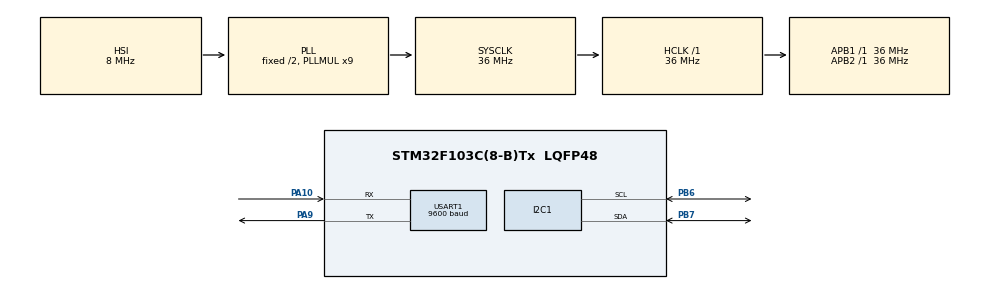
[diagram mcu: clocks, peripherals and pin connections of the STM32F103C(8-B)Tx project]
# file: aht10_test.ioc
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Mcu.Family=STM32F1
Mcu.Name=STM32F103C(8-B)Tx
Mcu.Package=LQFP48
NVIC.PriorityGroup=NVIC_PRIORITYGROUP_4
NVIC.TIM3_IRQn=true\:15\:0\:false\:false\:true\:false\:true\:true
NVIC.TimeBase=TIM3_IRQn
NVIC.TimeBaseIP=TIM3
PA10.Mode=Asynchronous
PA10.Signal=USART1_RX
PA13.Mode=Serial_Wire
PA13.Signal=SYS_JTMS-SWDIO
PA14.Mode=Serial_Wire
PA14.Signal=SYS_JTCK-SWCLK
PA9.Mode=Asynchronous
PA9.Signal=USART1_TX
PB6.Mode=I2C
PB6.Signal=I2C1_SCL
PB7.Mode=I2C
PB7.Signal=I2C1_SDA
ProjectManager.HeapSize=0x200
ProjectManager.StackSize=0x400
ProjectManager.TargetToolchain=STM32CubeIDE
RCC.AHBFreq_Value=36000000
RCC.APB1Freq_Value=36000000
RCC.APB1TimFreq_Value=36000000
RCC.APB2Freq_Value=36000000
RCC.APB2TimFreq_Value=36000000
RCC.HCLKFreq_Value=36000000
RCC.PLLMUL=RCC_PLL_MUL9
RCC.SYSCLKFreq_VALUE=36000000
RCC.SYSCLKSource=RCC_SYSCLKSOURCE_PLLCLK
RCC.USBFreq_Value=36000000
USART1.BaudRate=9600
USART1.VirtualMode=VM_ASYNC
VP_SYS_VS_tim3.Mode=TIM3
board=custom

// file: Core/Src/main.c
/* USER CODE BEGIN Header */
/**
  ******************************************************************************
  * @file           : main.c
  * @brief          : Main program body
  ******************************************************************************
  * @attention
  *
  * Copyright (c) 2022 STMicroelectronics.
  * All rights reserved.
  *
  * This software is licensed under terms that can be found in the LICENSE file
  * in the root directory of this software component.
  * If no LICENSE file comes with this software, it is provided AS-IS.
  *
  ******************************************************************************
  */
/* USER CODE END Header */
#include "main.h"
#include "i2c.h"
#include "usart.h"
#include "gpio.h"

/* USER CODE BEGIN Includes */
#include "stdio.h"
#include "aht10.h"
/* USER CODE END Includes */

void SystemClock_Config(void);

/* USER CODE BEGIN 0 */
#ifdef __GNUC__
  #define PUTCHAR_PROTOTYPE int __io_putchar(int ch)
#else
  #define PUTCHAR_PROTOTYPE int fputc(int ch, FILE *f)
#endif

PUTCHAR_PROTOTYPE
{
	huart1.Instance->DR = (uint8_t) ch;
//	HAL_UART_Transmit(&huart1,(uint8_t *)&ch,1,0xFFFF);
	while(__HAL_UART_GET_FLAG(&huart1, UART_FLAG_TC) == RESET){}
  return ch;
}
/* USER CODE END 0 */

int main(void)
{

  /* MCU Configuration--------------------------------------------------------*/

  /* Reset of all peripherals, Initializes the Flash interface and the Systick. */
  HAL_Init();

  /* Configure the system clock */
  SystemClock_Config();

  /* Initialize all configured peripherals */
  MX_GPIO_Init();
  MX_I2C1_Init();
  MX_USART1_UART_Init();
  /* USER CODE BEGIN 2 */
  aht10_init();
  /* USER CODE END 2 */

  /* Infinite loop */
  while (1)
  {
	  aht10_read_data();
	  HAL_Delay(2000);
  }
}

void SystemClock_Config(void)
{
  RCC_OscInitTypeDef RCC_OscInitStruct = {0};
  RCC_ClkInitTypeDef RCC_ClkInitStruct = {0};

  /** Initializes the RCC Oscillators according to the specified parameters
  * in the RCC_OscInitTypeDef structure.
  */
  RCC_OscInitStruct.OscillatorType = RCC_OSCILLATORTYPE_HSI;
  RCC_OscInitStruct.HSIState = RCC_HSI_ON;
  RCC_OscInitStruct.HSICalibrationValue = RCC_HSICALIBRATION_DEFAULT;
  RCC_OscInitStruct.PLL.PLLState = RCC_PLL_ON;
  RCC_OscInitStruct.PLL.PLLSource = RCC_PLLSOURCE_HSI_DIV2;
  RCC_OscInitStruct.PLL.PLLMUL = RCC_PLL_MUL9;
  if (HAL_RCC_OscConfig(&RCC_OscInitStruct) != HAL_OK)
  {
    Error_Handler();
  }

  /** Initializes the CPU, AHB and APB buses clocks
  */
  RCC_ClkInitStruct.ClockType = RCC_CLOCKTYPE_HCLK|RCC_CLOCKTYPE_SYSCLK
                              |RCC_CLOCKTYPE_PCLK1|RCC_CLOCKTYPE_PCLK2;
  RCC_ClkInitStruct.SYSCLKSource = RCC_SYSCLKSOURCE_PLLCLK;
  RCC_ClkInitStruct.AHBCLKDivider = RCC_SYSCLK_DIV1;
  RCC_ClkInitStruct.APB1CLKDivider = RCC_HCLK_DIV1;
  RCC_ClkInitStruct.APB2CLKDivider = RCC_HCLK_DIV1;

  if (HAL_RCC_ClockConfig(&RCC_ClkInitStruct, FLASH_LATENCY_1) != HAL_OK)
  {
    Error_Handler();
  }
}

void HAL_TIM_PeriodElapsedCallback(TIM_HandleTypeDef *htim)
{
  if (htim->Instance == TIM3) {
    HAL_IncTick();
  }
}

void Error_Handler(void)
{
  __disable_irq();
  while (1)
  {
  }
}
